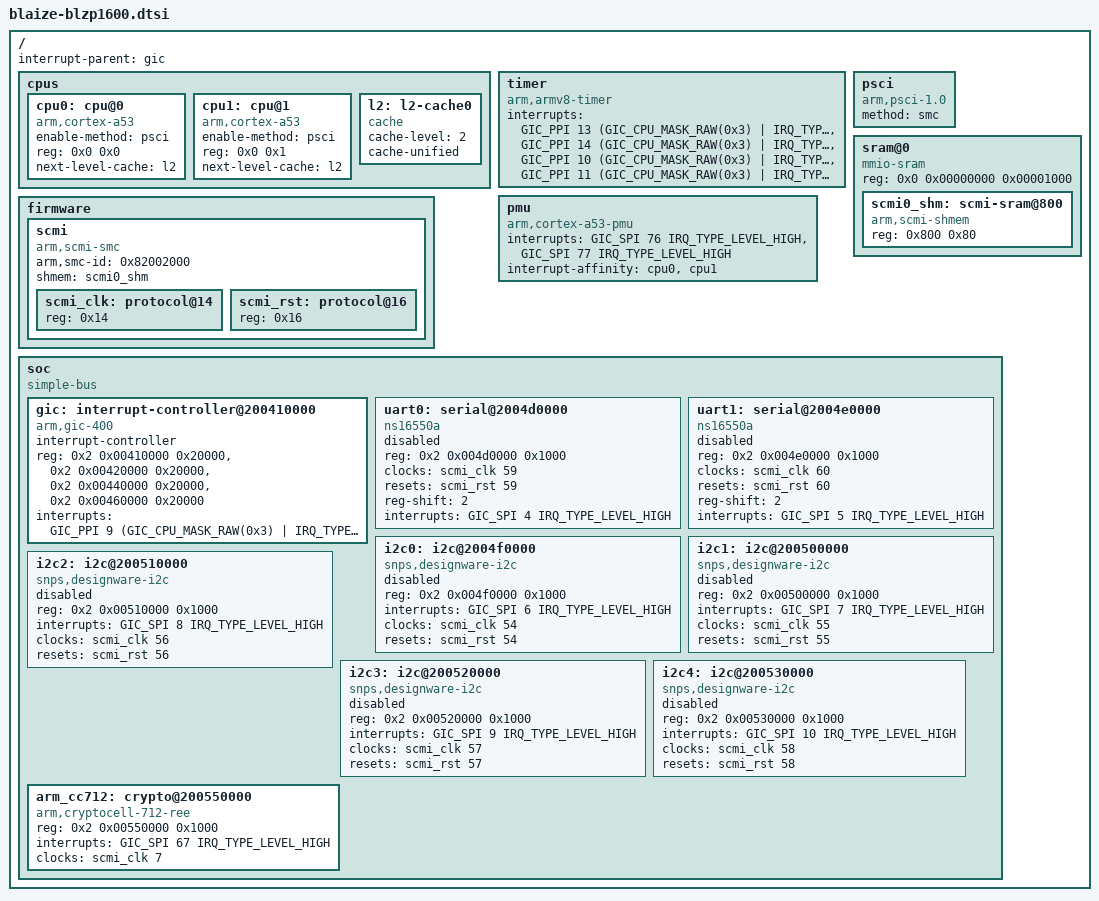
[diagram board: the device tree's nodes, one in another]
// SPDX-License-Identifier: GPL-2.0
/*
 * Copyright (c) 2023 Blaize, Inc. All rights reserved.
 */

#include <dt-bindings/gpio/gpio.h>
#include <dt-bindings/interrupt-controller/arm-gic.h>

/ {
	interrupt-parent = <&gic>;
	#address-cells = <2>;
	#size-cells = <1>;

	cpus {
		#address-cells = <2>;
		#size-cells = <0>;

		cpu0: cpu@0 {
			compatible = "arm,cortex-a53";
			device_type = "cpu";
			enable-method = "psci";
			reg = <0x0 0x0>;
			next-level-cache = <&l2>;
		};

		cpu1: cpu@1 {
			compatible = "arm,cortex-a53";
			device_type = "cpu";
			enable-method = "psci";
			reg = <0x0 0x1>;
			next-level-cache = <&l2>;
		};

		l2: l2-cache0 {
			compatible = "cache";
			cache-level = <2>;
			cache-unified;
		};
	};

	timer {
		compatible = "arm,armv8-timer";
		interrupts = /* Physical Secure PPI */
			     <GIC_PPI 13 (GIC_CPU_MASK_RAW(0x3) |
					  IRQ_TYPE_LEVEL_LOW)>,
			     /* Physical Non-Secure PPI */
			     <GIC_PPI 14 (GIC_CPU_MASK_RAW(0x3) |
					  IRQ_TYPE_LEVEL_LOW)>,
			     /* Hypervisor PPI */
			     <GIC_PPI 10 (GIC_CPU_MASK_RAW(0x3) |
					  IRQ_TYPE_LEVEL_LOW)>,
			     /* Virtual PPI */
			     <GIC_PPI 11 (GIC_CPU_MASK_RAW(0x3) |
					  IRQ_TYPE_LEVEL_LOW)>;
	};

	psci {
		compatible = "arm,psci-1.0", "arm,psci-0.2";
		method = "smc";
	};

	pmu {
		compatible = "arm,cortex-a53-pmu";
		interrupts = <GIC_SPI 76 IRQ_TYPE_LEVEL_HIGH>,
			     <GIC_SPI 77 IRQ_TYPE_LEVEL_HIGH>;
		interrupt-affinity = <&cpu0>, <&cpu1>;
	};

	sram@0 {
		/*
		 * On BLZP1600 there is no general purpose (non-secure) SRAM.
		 * A small DDR memory space has been reserved for general use.
		 */
		compatible = "mmio-sram";
		reg = <0x0 0x00000000 0x00001000>;
		#address-cells = <1>;
		#size-cells = <1>;
		ranges = <0 0x0 0x00000000 0x1000>;

		/* SCMI reserved buffer space on DDR space */
		scmi0_shm: scmi-sram@800 {
			compatible = "arm,scmi-shmem";
			reg = <0x800 0x80>;
		};
	};

	firmware {
		scmi {
			compatible = "arm,scmi-smc";
			arm,smc-id = <0x82002000>;
			#address-cells = <1>;
			#size-cells = <0>;

			shmem = <&scmi0_shm>;

			scmi_clk: protocol@14 {
				reg = <0x14>;
				#clock-cells = <1>;
			};

			scmi_rst: protocol@16 {
				reg = <0x16>;
				#reset-cells = <1>;
			};
		};
	};

	soc {
		compatible = "simple-bus";
		#address-cells = <2>;
		#size-cells = <1>;
		ranges;

		gic: interrupt-controller@200410000 {
			compatible = "arm,gic-400";
			#interrupt-cells = <3>;
			#address-cells = <0>;
			interrupt-controller;
			reg = <0x2 0x00410000 0x20000>,
			      <0x2 0x00420000 0x20000>,
			      <0x2 0x00440000 0x20000>,
			      <0x2 0x00460000 0x20000>;
			interrupts = <GIC_PPI 9 (GIC_CPU_MASK_RAW(0x3) |
						 IRQ_TYPE_LEVEL_LOW)>;
		};

		uart0: serial@2004d0000 {
			compatible = "ns16550a";
			reg = <0x2 0x004d0000 0x1000>;
			clocks = <&scmi_clk 59>;
			resets = <&scmi_rst 59>;
			reg-shift = <2>;
			interrupts = <GIC_SPI 4 IRQ_TYPE_LEVEL_HIGH>;
			status = "disabled";
		};

		uart1: serial@2004e0000 {
			compatible = "ns16550a";
			reg = <0x2 0x004e0000 0x1000>;
			clocks = <&scmi_clk 60>;
			resets = <&scmi_rst 60>;
			reg-shift = <2>;
			interrupts = <GIC_SPI 5 IRQ_TYPE_LEVEL_HIGH>;
			status = "disabled";
		};

		i2c0: i2c@2004f0000 {
			compatible = "snps,designware-i2c";
			reg = <0x2 0x004f0000 0x1000>;
			interrupts = <GIC_SPI 6 IRQ_TYPE_LEVEL_HIGH>;
			clocks = <&scmi_clk 54>;
			resets = <&scmi_rst 54>;
			#address-cells = <1>;
			#size-cells = <0>;
			status = "disabled";
		};

		i2c1: i2c@200500000 {
			compatible = "snps,designware-i2c";
			reg = <0x2 0x00500000 0x1000>;
			interrupts = <GIC_SPI 7 IRQ_TYPE_LEVEL_HIGH>;
			clocks = <&scmi_clk 55>;
			resets = <&scmi_rst 55>;
			#address-cells = <1>;
			#size-cells = <0>;
			status = "disabled";
		};

		i2c2: i2c@200510000 {
			compatible = "snps,designware-i2c";
			reg = <0x2 0x00510000 0x1000>;
			interrupts = <GIC_SPI 8 IRQ_TYPE_LEVEL_HIGH>;
			clocks = <&scmi_clk 56>;
			resets = <&scmi_rst 56>;
			#address-cells = <1>;
			#size-cells = <0>;
			status = "disabled";
		};

		i2c3: i2c@200520000 {
			compatible = "snps,designware-i2c";
			reg = <0x2 0x00520000 0x1000>;
			interrupts = <GIC_SPI 9 IRQ_TYPE_LEVEL_HIGH>;
			clocks = <&scmi_clk 57>;
			resets = <&scmi_rst 57>;
			#address-cells = <1>;
			#size-cells = <0>;
			status = "disabled";
		};

		i2c4: i2c@200530000 {
			compatible = "snps,designware-i2c";
			reg = <0x2 0x00530000 0x1000>;
			interrupts = <GIC_SPI 10 IRQ_TYPE_LEVEL_HIGH>;
			clocks = <&scmi_clk 58>;
			resets = <&scmi_rst 58>;
			#address-cells = <1>;
			#size-cells = <0>;
			status = "disabled";
		};

		arm_cc712: crypto@200550000 {
			compatible = "arm,cryptocell-712-ree";
			reg = <0x2 0x00550000 0x1000>;
			interrupts = <GIC_SPI 67 IRQ_TYPE_LEVEL_HIGH>;
			clocks = <&scmi_clk 7>;
		};
	};
};
